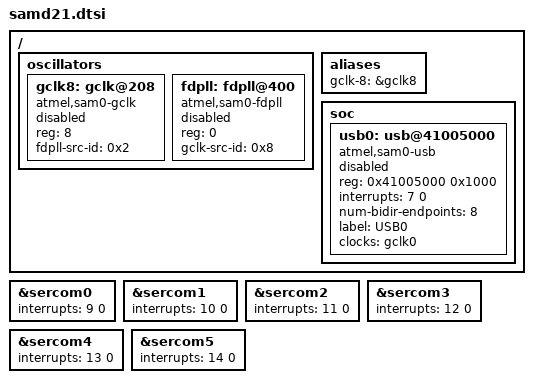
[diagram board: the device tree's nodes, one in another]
/*
 * Copyright (c) 2017 Google LLC.
 *
 * SPDX-License-Identifier: Apache-2.0
 */

#include <atmel/samd.dtsi>

/ {
	oscillators {
		gclk8: gclk@208 {
			compatible = "atmel,sam0-gclk";
			reg = <8>;
			fdpll-src-id = <0x2>;
			#clock-cells = <0>;
			status = "disabled";
		};

		fdpll: fdpll@400 {
			compatible = "atmel,sam0-fdpll";
			reg = <0>;
			gclk-src-id = <0x8>;
			#clock-cells = <0>;
			status = "disabled";
		};
	};

	aliases {
		gclk-8 = &gclk8;
	};

	soc {
		usb0: usb@41005000 {
			compatible = "atmel,sam0-usb";
			status = "disabled";
			reg = <0x41005000 0x1000>;
			interrupts = <7 0>;
			num-bidir-endpoints = <8>;
			label = "USB0";
			clocks = <&gclk0>;
		};
	};
};

&sercom0 {
	interrupts = <9 0>;
};

&sercom1 {
	interrupts = <10 0>;
};

&sercom2 {
	interrupts = <11 0>;
};

&sercom3 {
	interrupts = <12 0>;
};

&sercom4 {
	interrupts = <13 0>;
};

&sercom5 {
	interrupts = <14 0>;
};
